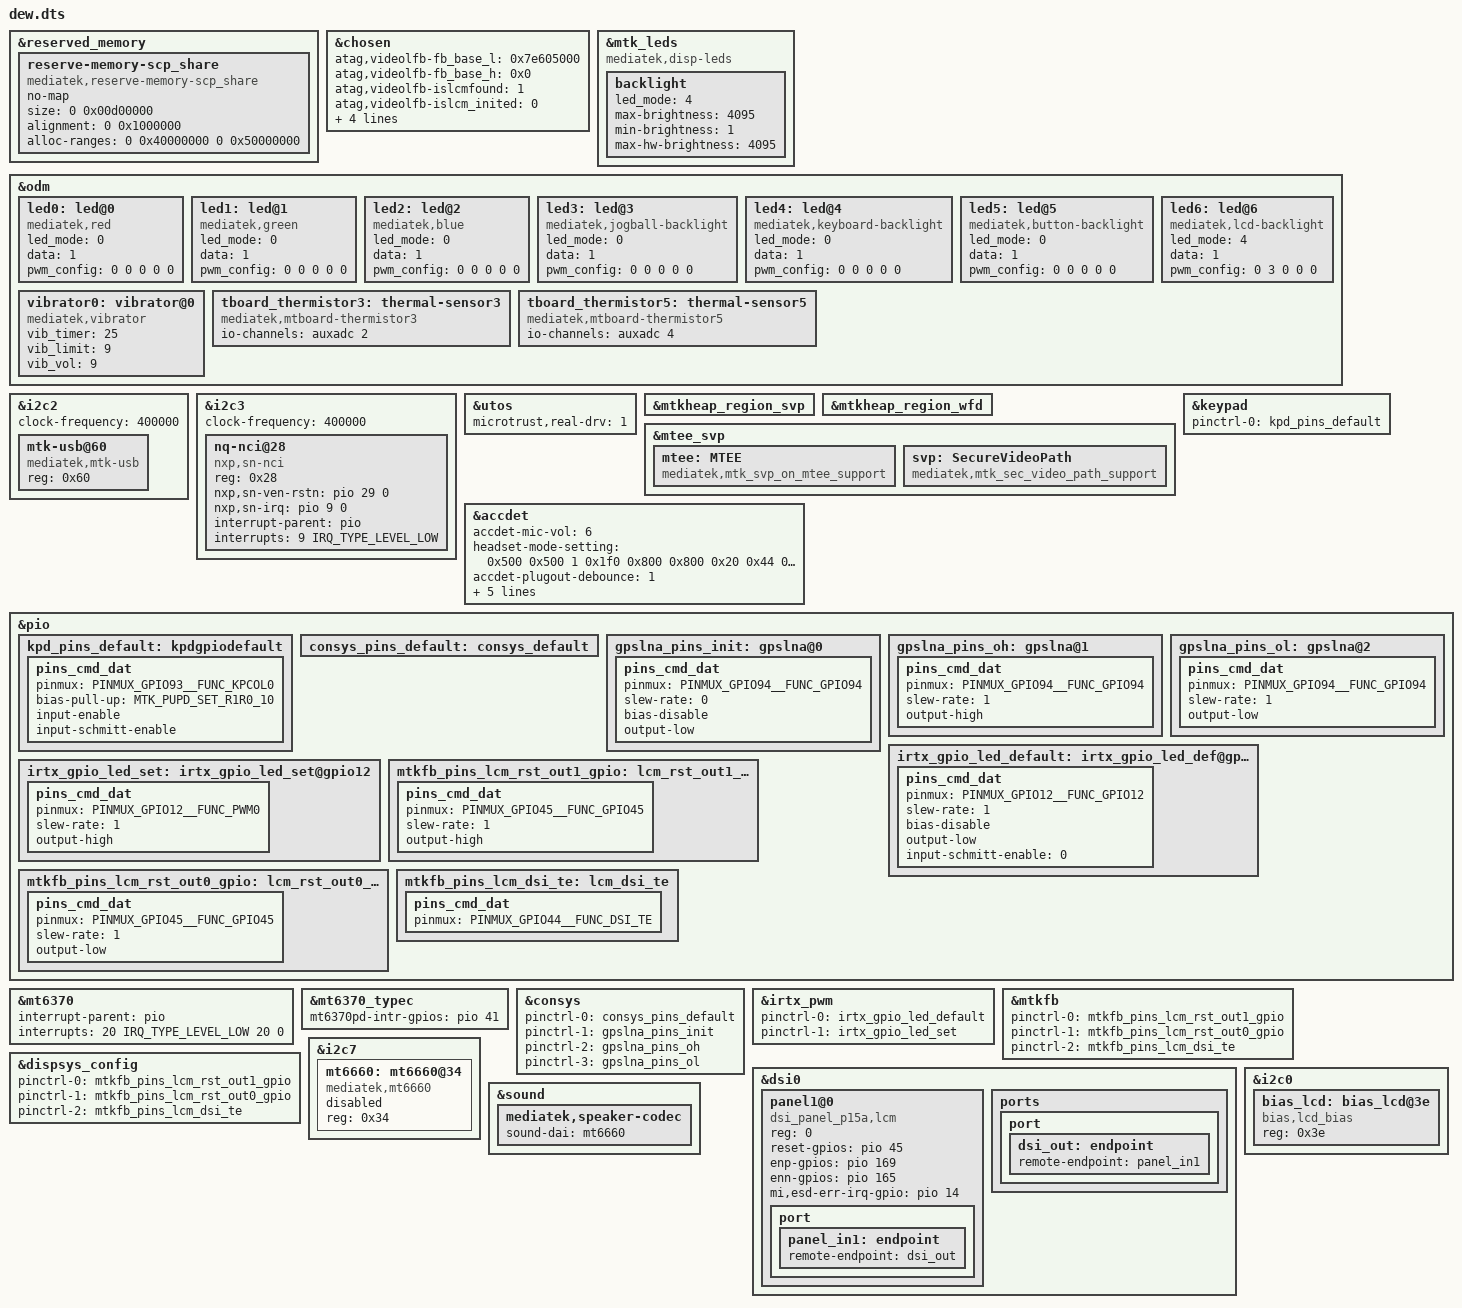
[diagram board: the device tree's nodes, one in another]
// SPDX-License-Identifier: GPL-2.0
/*
 * Copyright (c) 2019 MediaTek Inc.
 */

/dts-v1/;
/plugin/;
#include <dt-bindings/interrupt-controller/irq.h>
#include <dt-bindings/interrupt-controller/arm-gic.h>
#include <dt-bindings/pinctrl/mt6768-pinfunc.h>
#include "mediatek/touchscreen.dtsi"
#include "mediatek/xiaomi_connectivity.dtsi"
#include <dew_overlay.dtsi>

&reserved_memory {
	reserve-memory-scp_share {
		compatible = "mediatek,reserve-memory-scp_share";
		no-map;
		size = <0 0x00d00000>;
		alignment = <0 0x1000000>;
		alloc-ranges = <0 0x40000000 0 0x50000000>;
	};
};

/* chosen */
&chosen {

	atag,videolfb-fb_base_l = <0x7e605000>;
	atag,videolfb-fb_base_h = <0x0>;
	atag,videolfb-islcmfound = <1>;
	atag,videolfb-islcm_inited = <0>;
	atag,videolfb-fps= <6000>;
	atag,videolfb-vramSize= <0x017e8000>;
	atag,videolfb-lcmname=
		"hx83112b_fhdp_dsi_cmd_auo_rt5081_drv";
};

&mtk_leds {
	compatible = "mediatek,disp-leds";
	backlight {
		led_mode = <4>;
		max-brightness = <4095>;
		min-brightness = <1>;
		max-hw-brightness = <4095>;
	};
};

&odm {
	led0:led@0 {
		compatible = "mediatek,red";
		led_mode = <0>;
		data = <1>;
		pwm_config = <0 0 0 0 0>;
	};
	led1:led@1 {
		compatible = "mediatek,green";
		led_mode = <0>;
		data = <1>;
		pwm_config = <0 0 0 0 0>;
	};
	led2:led@2 {
		compatible = "mediatek,blue";
		led_mode = <0>;
		data = <1>;
		pwm_config = <0 0 0 0 0>;
	};
	led3:led@3 {
		compatible = "mediatek,jogball-backlight";
		led_mode = <0>;
		data = <1>;
		pwm_config = <0 0 0 0 0>;
	};
	led4:led@4 {
		compatible = "mediatek,keyboard-backlight";
		led_mode = <0>;
		data = <1>;
		pwm_config = <0 0 0 0 0>;
	};
	led5:led@5 {
		compatible = "mediatek,button-backlight";
		led_mode = <0>;
		data = <1>;
		pwm_config = <0 0 0 0 0>;
	};
	led6:led@6 {
		compatible = "mediatek,lcd-backlight";
		led_mode = <4>;
		data = <1>;
		pwm_config = <0 3 0 0 0>;
	};
	vibrator0:vibrator@0 {
		compatible = "mediatek,vibrator";
		vib_timer = <25>;
		vib_limit = <9>;
		vib_vol= <9>;
	};

	/* add auxadc 2(usb ntc) start */
	tboard_thermistor3: thermal-sensor3 {
		compatible = "mediatek,mtboard-thermistor3";
		io-channels = <&auxadc 2>;
		io-channel-names = "thermistor-ch2";
	};
	/* add auxadc 2(usb ntc) end */

	/* add auxadc 4(charge ic ntc) start */
	tboard_thermistor5: thermal-sensor5 {
		compatible = "mediatek,mtboard-thermistor5";
		io-channels = <&auxadc 4>;
		io-channel-names = "thermistor-ch4";
	};
	/* add auxadc 4(charge ic ntc) end */
};

&i2c2 {
	clock-frequency = <400000>;

	mtk-usb@60 {
		compatible = "mediatek,mtk-usb";
		reg = <0x60>;
		status = "okay";
	};
};

&i2c3 {
	status = "okay";
        clock-frequency = <400000>;
        nq-nci@28 {
		compatible = "nxp,sn-nci";
		reg = <0x28>;
		nxp,sn-ven-rstn = <&pio 29 0>;
		nxp,sn-irq = <&pio 9 0>;
		interrupt-parent = <&pio>;
		interrupts = <9 IRQ_TYPE_LEVEL_LOW>;
		status = "okay";
        };
};

&utos {
	microtrust,real-drv = <1>;
};

&mtkheap_region_svp {
	status = "ok";
};

&mtkheap_region_wfd {
	status = "ok";
};

&mtee_svp {
	mtee: MTEE {
		compatible = "mediatek,mtk_svp_on_mtee_support";
	};

	svp: SecureVideoPath {
		compatible = "mediatek,mtk_sec_video_path_support";
	};
};

/* accdet start */
&accdet {
	/* accdet micbias voltage: 0x07,2.7v;0x05,2.5v;0x02,1.9v */
	accdet-mic-vol = <6>;
	headset-mode-setting = <0x500 0x500 1 0x1f0
				0x800 0x800 0x20 0x44
				0x00 0x00
				0xe 0x00 0x00 0x00 0x00>;
	accdet-plugout-debounce = <1>;
	/*1:ACC mode, 2:low cost without in bias, 6:low cost with in bias*/
	accdet-mic-mode = <1>;
	/* eint_level_trigger: 8,LEVEL_LOW(DEF) ;4,LV_HIGH;others,LV_LOW */
	headset-eint-level-pol = <8>;
	/*0--MD_MAX--UP_MAX--DW_MAX*/
	headset-three-key-threshold = <0 80 220 400>;
	headset-three-key-threshold-CDD = <0 121 192 600>;
	/*0--MD_MAX--VOICE_MAX--UP_MAX--DW_MAX*/
	headset-four-key-threshold = <0 58 121 192 400>;
	status = "okay";
};
/* accdet end */

/* keypad start */
&keypad {
	pinctrl-names = "default";
	pinctrl-0 = <&kpd_pins_default>;
};

&pio {
	kpd_pins_default: kpdgpiodefault {
		pins_cmd_dat {
			pinmux = <PINMUX_GPIO93__FUNC_KPCOL0>;
			bias-pull-up = <MTK_PUPD_SET_R1R0_10>;
			input-enable;
			input-schmitt-enable;
		};
	};
};
/* keypad end */

&mt6370 {
	interrupt-parent = <&pio>;
	interrupts = <20 IRQ_TYPE_LEVEL_LOW 20 0>;
};

&mt6370_typec {
	mt6370pd-intr-gpios = <&pio 41 0>;
};

/* CONSYS GPIO standardization */
&pio {
	consys_pins_default: consys_default {
	};
	gpslna_pins_init: gpslna@0 {
		pins_cmd_dat {
			pinmux = <PINMUX_GPIO94__FUNC_GPIO94>;
			slew-rate = <0>;
			bias-disable;
			output-low;
		};
	};
	gpslna_pins_oh: gpslna@1 {
		pins_cmd_dat {
			pinmux = <PINMUX_GPIO94__FUNC_GPIO94>;
			slew-rate = <1>;
			output-high;
		};
	};
	gpslna_pins_ol: gpslna@2 {
		pins_cmd_dat {
			pinmux = <PINMUX_GPIO94__FUNC_GPIO94>;
			slew-rate = <1>;
			output-low;
		};
	};
};
&consys {
	pinctrl-names = "default", "gps_lna_state_init",
		"gps_lna_state_oh", "gps_lna_state_ol";
	pinctrl-0 = <&consys_pins_default>;
	pinctrl-1 = <&gpslna_pins_init>;
	pinctrl-2 = <&gpslna_pins_oh>;
	pinctrl-3 = <&gpslna_pins_ol>;
	status = "okay";
};
/* CONSYS end */

/* IRTX GPIO Start */
&irtx_pwm {
	pinctrl-names = "irtx_gpio_led_default", "irtx_gpio_led_set";
	pinctrl-0 = <&irtx_gpio_led_default>;
	pinctrl-1 = <&irtx_gpio_led_set>;
	status = "okay";
};
&pio {
	/* IRTX GPIO Settings -Start */
	/* default: GPIO0, output, high */
	irtx_gpio_led_default:irtx_gpio_led_def@gpio12 {
		pins_cmd_dat {
			pinmux = <PINMUX_GPIO12__FUNC_GPIO12>;
			slew-rate = <1>;
			bias-disable;
			output-low;
			input-schmitt-enable = <0>;
		};
	};

	irtx_gpio_led_set:irtx_gpio_led_set@gpio12 {
		pins_cmd_dat {
			pinmux = <PINMUX_GPIO12__FUNC_PWM0>;
			slew-rate = <1>;
			output-high;
		};
	};
}; /* IRTX GPIO Settings -End */

/* DISPSYS GPIO standardization */
&pio {
	mtkfb_pins_lcm_rst_out1_gpio: lcm_rst_out1_gpio {
		pins_cmd_dat {
			pinmux = <PINMUX_GPIO45__FUNC_GPIO45>;
			slew-rate = <1>;
			output-high;
		};
	};

	mtkfb_pins_lcm_rst_out0_gpio: lcm_rst_out0_gpio {
		pins_cmd_dat {
			pinmux = <PINMUX_GPIO45__FUNC_GPIO45>;
			slew-rate = <1>;
			output-low;
		};
	};

	mtkfb_pins_lcm_dsi_te: lcm_dsi_te {
		pins_cmd_dat {
			pinmux = <PINMUX_GPIO44__FUNC_DSI_TE>;
		};
	};
};

&mtkfb {
	pinctrl-names =
		"lcm_rst_out1_gpio", "lcm_rst_out0_gpio",
		"mode_te_te";
	pinctrl-0 = <&mtkfb_pins_lcm_rst_out1_gpio>;
	pinctrl-1 = <&mtkfb_pins_lcm_rst_out0_gpio>;
	pinctrl-2 = <&mtkfb_pins_lcm_dsi_te>;
	status = "okay";
};

&dispsys_config {
	pinctrl-names =
		"lcm_rst_out1_gpio", "lcm_rst_out0_gpio",
		"mode_te_te";
	pinctrl-0 = <&mtkfb_pins_lcm_rst_out1_gpio>;
	pinctrl-1 = <&mtkfb_pins_lcm_rst_out0_gpio>;
	pinctrl-2 = <&mtkfb_pins_lcm_dsi_te>;
	status = "okay";
};

&dsi0 {
	status = "okay";
	#address-cells = <1>;
	#size-cells = <0>;
	panel1@0 {
		compatible = "dsi_panel_p15a,lcm";
		reg = <0>;
		reset-gpios = <&pio 45 0>;
		enp-gpios = <&pio 169 0>;
		enn-gpios = <&pio 165 0>;
		mi,esd-err-irq-gpio = <&pio 14 0x2002>;
		status = "okay";
		port {
			panel_in1: endpoint {
				remote-endpoint = <&dsi_out>;
			};
		};
	};
	ports {
		port {
			dsi_out: endpoint {
				remote-endpoint = <&panel_in1>;
			};
		};
	};
};

&i2c0 {
	bias_lcd:bias_lcd@3e {
		compatible = "bias,lcd_bias";
		reg = <0x3e>;
		status = "okay";
		// enn-gpios;
		// enp-gpios;
	};
};

&i2c7 {
	mt6660: mt6660@34 {
		compatible = "mediatek,mt6660";
		#sound-dai-cells = <0>;
		reg = <0x34>;
		status = "disabled";
	};
};

&sound {
	mediatek,speaker-codec {
		sound-dai = <&mt6660>;
	};
};

/* DISPSYS GPIO standardization end*/

#include <dew/cust.dtsi>
#include "mediatek/cust_mt6768_camera.dtsi"
#include "mediatek/fingerprint.dtsi"
#include "mediatek/cust_mt6768_touch_1080x2160.dtsi"
#include "mediatek/mt6895-sia81x9.dtsi"
#include "mediatek/fs18xx.dtsi"
#include "mediatek/oca72xxx.dtsi"
/*End of this file, DO NOT ADD ANYTHING HERE*/
